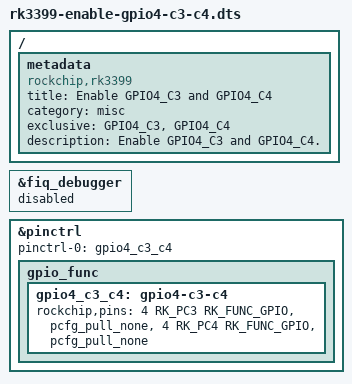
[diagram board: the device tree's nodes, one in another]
/dts-v1/;
/plugin/;

#include <dt-bindings/pinctrl/rockchip.h>

/ {
	metadata {
		title = "Enable GPIO4_C3 and GPIO4_C4";
		compatible = "rockchip,rk3399";
		category = "misc";
		exclusive = "GPIO4_C3", "GPIO4_C4";
		description = "Enable GPIO4_C3 and GPIO4_C4.";
	};

	fragment@0 {
		target = <&fiq_debugger>;

		__overlay__ {
			status = "disabled";
		};
	};

	fragment@1 {
		target = <&pinctrl>;

		__overlay__ {
			pinctrl-0 = <&gpio4_c3_c4>;
			pinctrl-names = "default";

			gpio_func {
				gpio4_c3_c4: gpio4-c3-c4 {
					rockchip,pins =
						/* GPIO4_C3 */
						<4 RK_PC3 RK_FUNC_GPIO &pcfg_pull_none>,
						/* GPIO4_C4 */
						<4 RK_PC4 RK_FUNC_GPIO &pcfg_pull_none>;
				};
			};
		};
	};
};
